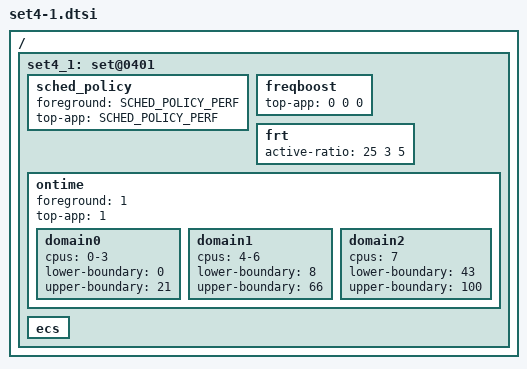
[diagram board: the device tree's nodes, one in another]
/ {
	/* balance mode - touch boost */
	set4_1: set@0401{
		/* schedudling policy */
		sched_policy {
			foreground 		= <SCHED_POLICY_PERF>;
			top-app			= <SCHED_POLICY_PERF>;
		};

		/* Boosting margin applied to frequency selection */
		freqboost {	   		/* LIT MED BIG */
			top-app         	= <  0  0  0>;
		};

		frt {	   			/* LIT MED BIG */
			active-ratio 		= < 25   3   5>;
		};

		/* Ontime Migration */
		ontime {
			foreground 	= <1>;
			top-app		= <1>;

			domain0 {
				cpus = "0-3";
				lower-boundary = <0>;
				upper-boundary = <21>;
			};
			domain1 {
				cpus = "4-6";
				lower-boundary = <8>;
				upper-boundary = <66>;
			};
			domain2 {
				cpus = "7";
				lower-boundary = <43>;
				upper-boundary = <100>;
			};
		};

		ecs { };
	};
};
